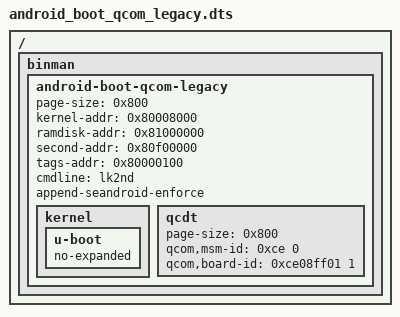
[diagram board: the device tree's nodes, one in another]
// SPDX-License-Identifier: GPL-2.0+

/dts-v1/;

/ {
	#address-cells = <1>;
	#size-cells = <1>;

	binman {
		android-boot-qcom-legacy {
			page-size = <0x800>;
			kernel-addr = <0x80008000>;
			ramdisk-addr = <0x81000000>;
			second-addr = <0x80f00000>;
			tags-addr = <0x80000100>;
			cmdline = "lk2nd";
			append-seandroid-enforce;

			kernel {
				u-boot {
					no-expanded;
				};
			};

			qcdt {
				page-size = <0x800>;
				qcom,msm-id = <0xce 0>;
				qcom,board-id = <0xce08ff01 1>;
			};
		};
	};
};
